AUTOSAR XML (schema 4-2-2)
package /AUTOSAR_NvM/PortInterfaces
  6 x client server interface, all with is-service=true:
    NvMAdmin
      operation SetBlockProtection: possible-error=NvMAdmin/E_NOT_OK
        arg ProtectionEnabled: type=boolean, direction=IN
      error E_NOT_OK: error-code=1
    NvMMirror
      operation ReadRamBlockFromNvM: possible-error=NvMMirror/E_NOT_OK
        arg SrcPtr: type=NvM_Rb_VoidPtr, direction=IN
      operation WriteRamBlockToNvM: possible-error=NvMMirror/E_NOT_OK
        arg DstPtr: type=NvM_Rb_VoidPtr, direction=IN
      error E_NOT_OK: error-code=1
    NvMNotifyInitBlock
      operation InitBlock: possible-error=NvMNotifyInitBlock/E_NOT_OK
      error E_NOT_OK: error-code=1
    NvMNotifyJobFinished
      operation JobFinished: possible-error=NvMNotifyJobFinished/E_NOT_OK
        arg ServiceId: type=uint8, direction=IN
        arg JobResult: type=NvM_RequestResultType, direction=IN
      error E_NOT_OK: error-code=1
    NvMRbNotifyJobStarted
      operation JobStarted
        arg ServiceId: type=uint8, direction=IN
    NvMService
      12 x operation, all with possible-error=NvMService/E_NOT_OK:
        EraseBlock
        GetDataIndex
          arg DataIndexPtr: type=uint8, direction=OUT
        GetErrorStatus
          arg RequestResultPtr: type=NvM_RequestResultType, direction=OUT
        InvalidateNvBlock
        ReadBlock
          arg DstPtr: type=NvM_Rb_VoidPtr, direction=IN
        ReadPRAMBlock
        RestoreBlockDefaults
          arg DstPtr: type=NvM_Rb_VoidPtr, direction=IN
        RestorePRAMBlockDefaults
        SetDataIndex
          arg DataIndex: type=uint8, direction=IN
        SetRamBlockStatus
          arg BlockChanged: type=boolean, direction=IN
        WriteBlock
          arg SrcPtr: type=NvM_Rb_ConstVoidPtr, direction=IN
        WritePRAMBlock
      error E_NOT_OK: error-code=1
package /AUTOSAR_NvM/SwcImplementations
  swc implementation NvM: programming-language=C, swc-bsw-mapping=NvM, vendor-id=6, behavior=NVRAMManager
    code-descriptors:
      code CodeDescriptor: artifact-descriptors=autosar-engineering-object={short-label=ArEngObj, category=SWSRC}
package /AUTOSAR_NvM/SwComponentTypes
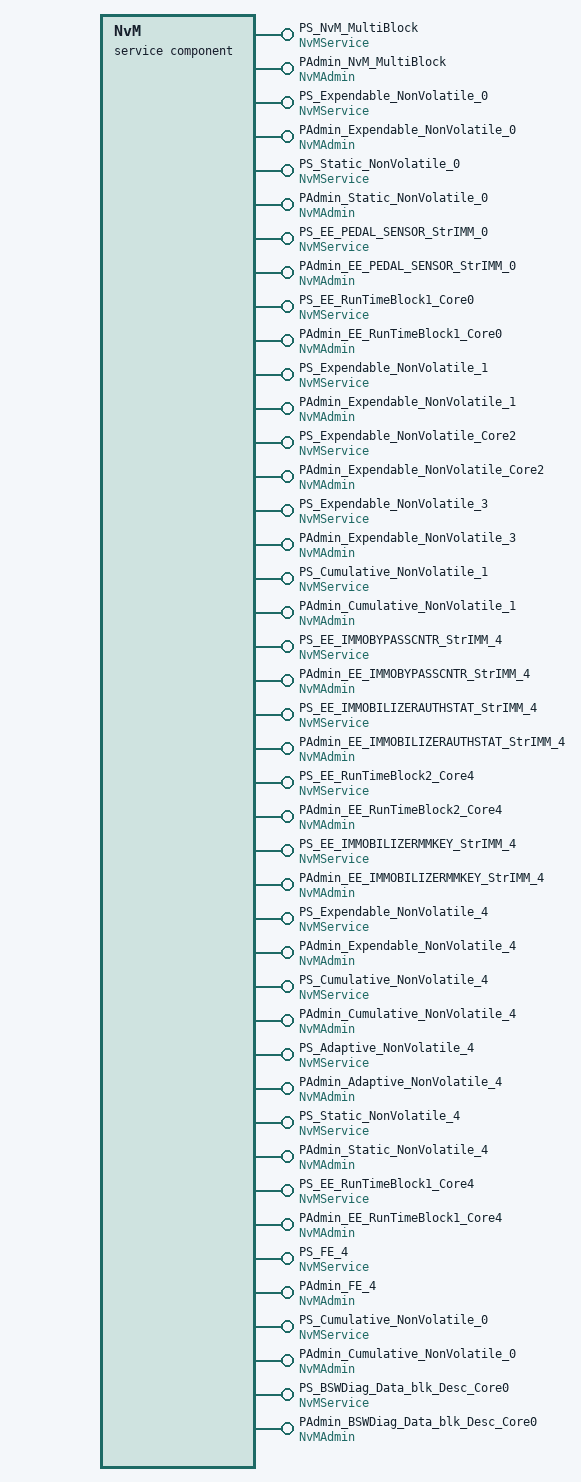
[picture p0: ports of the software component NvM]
  service sw component type NvM
    42 x provide port:
      PS_NvM_MultiBlock: provided-interface=NvMService
        provided-com-specs:
          operation=EraseBlock, queue-length=1
          operation=GetDataIndex, queue-length=1
          operation=GetErrorStatus, queue-length=1
          operation=InvalidateNvBlock, queue-length=1
          operation=ReadBlock, queue-length=1
          operation=ReadPRAMBlock, queue-length=1
          operation=RestoreBlockDefaults, queue-length=1
          operation=RestorePRAMBlockDefaults, queue-length=1
          operation=SetDataIndex, queue-length=1
          operation=SetRamBlockStatus, queue-length=1
          operation=WriteBlock, queue-length=1
          operation=WritePRAMBlock, queue-length=1
      PAdmin_NvM_MultiBlock: server-com-spec{operation=SetBlockProtection, queue-length=1}, provided-interface=NvMAdmin
      PS_Expendable_NonVolatile_0: provided-interface=NvMService
        provided-com-specs:
          operation=EraseBlock, queue-length=1
          operation=GetDataIndex, queue-length=1
          operation=GetErrorStatus, queue-length=1
          operation=InvalidateNvBlock, queue-length=1
          operation=ReadBlock, queue-length=1
          operation=ReadPRAMBlock, queue-length=1
          operation=RestoreBlockDefaults, queue-length=1
          operation=RestorePRAMBlockDefaults, queue-length=1
          operation=SetDataIndex, queue-length=1
          operation=SetRamBlockStatus, queue-length=1
          operation=WriteBlock, queue-length=1
          operation=WritePRAMBlock, queue-length=1
      PAdmin_Expendable_NonVolatile_0: server-com-spec{operation=SetBlockProtection, queue-length=1}, provided-interface=NvMAdmin
      PS_Static_NonVolatile_0: provided-interface=NvMService
        provided-com-specs:
          operation=EraseBlock, queue-length=1
          operation=GetDataIndex, queue-length=1
          operation=GetErrorStatus, queue-length=1
          operation=InvalidateNvBlock, queue-length=1
          operation=ReadBlock, queue-length=1
          operation=ReadPRAMBlock, queue-length=1
          operation=RestoreBlockDefaults, queue-length=1
          operation=RestorePRAMBlockDefaults, queue-length=1
          operation=SetDataIndex, queue-length=1
          operation=SetRamBlockStatus, queue-length=1
          operation=WriteBlock, queue-length=1
          operation=WritePRAMBlock, queue-length=1
      PAdmin_Static_NonVolatile_0: server-com-spec{operation=SetBlockProtection, queue-length=1}, provided-interface=NvMAdmin
      PS_EE_PEDAL_SENSOR_StrIMM_0: provided-interface=NvMService
        provided-com-specs:
          operation=EraseBlock, queue-length=1
          operation=GetDataIndex, queue-length=1
          operation=GetErrorStatus, queue-length=1
          operation=InvalidateNvBlock, queue-length=1
          operation=ReadBlock, queue-length=1
          operation=ReadPRAMBlock, queue-length=1
          operation=RestoreBlockDefaults, queue-length=1
          operation=RestorePRAMBlockDefaults, queue-length=1
          operation=SetDataIndex, queue-length=1
          operation=SetRamBlockStatus, queue-length=1
          operation=WriteBlock, queue-length=1
          operation=WritePRAMBlock, queue-length=1
      PAdmin_EE_PEDAL_SENSOR_StrIMM_0: server-com-spec{operation=SetBlockProtection, queue-length=1}, provided-interface=NvMAdmin
      PS_EE_RunTimeBlock1_Core0: provided-interface=NvMService
        provided-com-specs:
          operation=EraseBlock, queue-length=1
          operation=GetDataIndex, queue-length=1
          operation=GetErrorStatus, queue-length=1
          operation=InvalidateNvBlock, queue-length=1
          operation=ReadBlock, queue-length=1
          operation=ReadPRAMBlock, queue-length=1
          operation=RestoreBlockDefaults, queue-length=1
          operation=RestorePRAMBlockDefaults, queue-length=1
          operation=SetDataIndex, queue-length=1
          operation=SetRamBlockStatus, queue-length=1
          operation=WriteBlock, queue-length=1
          operation=WritePRAMBlock, queue-length=1
      PAdmin_EE_RunTimeBlock1_Core0: server-com-spec{operation=SetBlockProtection, queue-length=1}, provided-interface=NvMAdmin
      PS_Expendable_NonVolatile_1: provided-interface=NvMService
        provided-com-specs:
          operation=EraseBlock, queue-length=1
          operation=GetDataIndex, queue-length=1
          operation=GetErrorStatus, queue-length=1
          operation=InvalidateNvBlock, queue-length=1
          operation=ReadBlock, queue-length=1
          operation=ReadPRAMBlock, queue-length=1
          operation=RestoreBlockDefaults, queue-length=1
          operation=RestorePRAMBlockDefaults, queue-length=1
          operation=SetDataIndex, queue-length=1
          operation=SetRamBlockStatus, queue-length=1
          operation=WriteBlock, queue-length=1
          operation=WritePRAMBlock, queue-length=1
      PAdmin_Expendable_NonVolatile_1: server-com-spec{operation=SetBlockProtection, queue-length=1}, provided-interface=NvMAdmin
      PS_Expendable_NonVolatile_Core2: provided-interface=NvMService
        provided-com-specs:
          operation=EraseBlock, queue-length=1
          operation=GetDataIndex, queue-length=1
          operation=GetErrorStatus, queue-length=1
          operation=InvalidateNvBlock, queue-length=1
          operation=ReadBlock, queue-length=1
          operation=ReadPRAMBlock, queue-length=1
          operation=RestoreBlockDefaults, queue-length=1
          operation=RestorePRAMBlockDefaults, queue-length=1
          operation=SetDataIndex, queue-length=1
          operation=SetRamBlockStatus, queue-length=1
          operation=WriteBlock, queue-length=1
          operation=WritePRAMBlock, queue-length=1
      PAdmin_Expendable_NonVolatile_Core2: server-com-spec{operation=SetBlockProtection, queue-length=1}, provided-interface=NvMAdmin
      PS_Expendable_NonVolatile_3: provided-interface=NvMService
        provided-com-specs:
          operation=EraseBlock, queue-length=1
          operation=GetDataIndex, queue-length=1
          operation=GetErrorStatus, queue-length=1
          operation=InvalidateNvBlock, queue-length=1
          operation=ReadBlock, queue-length=1
          operation=ReadPRAMBlock, queue-length=1
          operation=RestoreBlockDefaults, queue-length=1
          operation=RestorePRAMBlockDefaults, queue-length=1
          operation=SetDataIndex, queue-length=1
          operation=SetRamBlockStatus, queue-length=1
          operation=WriteBlock, queue-length=1
          operation=WritePRAMBlock, queue-length=1
      PAdmin_Expendable_NonVolatile_3: server-com-spec{operation=SetBlockProtection, queue-length=1}, provided-interface=NvMAdmin
      PS_Cumulative_NonVolatile_1: provided-interface=NvMService
        provided-com-specs:
          operation=EraseBlock, queue-length=1
          operation=GetDataIndex, queue-length=1
          operation=GetErrorStatus, queue-length=1
          operation=InvalidateNvBlock, queue-length=1
          operation=ReadBlock, queue-length=1
          operation=ReadPRAMBlock, queue-length=1
          operation=RestoreBlockDefaults, queue-length=1
          operation=RestorePRAMBlockDefaults, queue-length=1
          operation=SetDataIndex, queue-length=1
          operation=SetRamBlockStatus, queue-length=1
          operation=WriteBlock, queue-length=1
          operation=WritePRAMBlock, queue-length=1
      PAdmin_Cumulative_NonVolatile_1: server-com-spec{operation=SetBlockProtection, queue-length=1}, provided-interface=NvMAdmin
      PS_EE_IMMOBYPASSCNTR_StrIMM_4: provided-interface=NvMService
        provided-com-specs:
          operation=EraseBlock, queue-length=1
          operation=GetDataIndex, queue-length=1
          operation=GetErrorStatus, queue-length=1
          operation=InvalidateNvBlock, queue-length=1
          operation=ReadBlock, queue-length=1
          operation=ReadPRAMBlock, queue-length=1
          operation=RestoreBlockDefaults, queue-length=1
          operation=RestorePRAMBlockDefaults, queue-length=1
          operation=SetDataIndex, queue-length=1
          operation=SetRamBlockStatus, queue-length=1
          operation=WriteBlock, queue-length=1
          operation=WritePRAMBlock, queue-length=1
      PAdmin_EE_IMMOBYPASSCNTR_StrIMM_4: server-com-spec{operation=SetBlockProtection, queue-length=1}, provided-interface=NvMAdmin
      PS_EE_IMMOBILIZERAUTHSTAT_StrIMM_4: provided-interface=NvMService
        provided-com-specs:
          operation=EraseBlock, queue-length=1
          operation=GetDataIndex, queue-length=1
          operation=GetErrorStatus, queue-length=1
          operation=InvalidateNvBlock, queue-length=1
          operation=ReadBlock, queue-length=1
          operation=ReadPRAMBlock, queue-length=1
          operation=RestoreBlockDefaults, queue-length=1
          operation=RestorePRAMBlockDefaults, queue-length=1
          operation=SetDataIndex, queue-length=1
          operation=SetRamBlockStatus, queue-length=1
          operation=WriteBlock, queue-length=1
          operation=WritePRAMBlock, queue-length=1
      PAdmin_EE_IMMOBILIZERAUTHSTAT_StrIMM_4: server-com-spec{operation=SetBlockProtection, queue-length=1}, provided-interface=NvMAdmin
      PS_EE_RunTimeBlock2_Core4: provided-interface=NvMService
        provided-com-specs:
          operation=EraseBlock, queue-length=1
          operation=GetDataIndex, queue-length=1
          operation=GetErrorStatus, queue-length=1
          operation=InvalidateNvBlock, queue-length=1
          operation=ReadBlock, queue-length=1
          operation=ReadPRAMBlock, queue-length=1
          operation=RestoreBlockDefaults, queue-length=1
          operation=RestorePRAMBlockDefaults, queue-length=1
          operation=SetDataIndex, queue-length=1
          operation=SetRamBlockStatus, queue-length=1
          operation=WriteBlock, queue-length=1
          operation=WritePRAMBlock, queue-length=1
      PAdmin_EE_RunTimeBlock2_Core4: server-com-spec{operation=SetBlockProtection, queue-length=1}, provided-interface=NvMAdmin
      PS_EE_IMMOBILIZERMMKEY_StrIMM_4: provided-interface=NvMService
        provided-com-specs:
          operation=EraseBlock, queue-length=1
          operation=GetDataIndex, queue-length=1
          operation=GetErrorStatus, queue-length=1
          operation=InvalidateNvBlock, queue-length=1
          operation=ReadBlock, queue-length=1
          operation=ReadPRAMBlock, queue-length=1
          operation=RestoreBlockDefaults, queue-length=1
          operation=RestorePRAMBlockDefaults, queue-length=1
          operation=SetDataIndex, queue-length=1
          operation=SetRamBlockStatus, queue-length=1
          operation=WriteBlock, queue-length=1
          operation=WritePRAMBlock, queue-length=1
      PAdmin_EE_IMMOBILIZERMMKEY_StrIMM_4: server-com-spec{operation=SetBlockProtection, queue-length=1}, provided-interface=NvMAdmin
      PS_Expendable_NonVolatile_4: provided-interface=NvMService
        provided-com-specs:
          operation=EraseBlock, queue-length=1
          operation=GetDataIndex, queue-length=1
          operation=GetErrorStatus, queue-length=1
          operation=InvalidateNvBlock, queue-length=1
          operation=ReadBlock, queue-length=1
          operation=ReadPRAMBlock, queue-length=1
          operation=RestoreBlockDefaults, queue-length=1
          operation=RestorePRAMBlockDefaults, queue-length=1
          operation=SetDataIndex, queue-length=1
          operation=SetRamBlockStatus, queue-length=1
          operation=WriteBlock, queue-length=1
          operation=WritePRAMBlock, queue-length=1
      PAdmin_Expendable_NonVolatile_4: server-com-spec{operation=SetBlockProtection, queue-length=1}, provided-interface=NvMAdmin
      PS_Cumulative_NonVolatile_4: provided-interface=NvMService
        provided-com-specs:
          operation=EraseBlock, queue-length=1
          operation=GetDataIndex, queue-length=1
          operation=GetErrorStatus, queue-length=1
          operation=InvalidateNvBlock, queue-length=1
          operation=ReadBlock, queue-length=1
          operation=ReadPRAMBlock, queue-length=1
          operation=RestoreBlockDefaults, queue-length=1
          operation=RestorePRAMBlockDefaults, queue-length=1
          operation=SetDataIndex, queue-length=1
          operation=SetRamBlockStatus, queue-length=1
          operation=WriteBlock, queue-length=1
          operation=WritePRAMBlock, queue-length=1
      PAdmin_Cumulative_NonVolatile_4: server-com-spec{operation=SetBlockProtection, queue-length=1}, provided-interface=NvMAdmin
      PS_Adaptive_NonVolatile_4: provided-interface=NvMService
        provided-com-specs:
          operation=EraseBlock, queue-length=1
          operation=GetDataIndex, queue-length=1
          operation=GetErrorStatus, queue-length=1
          operation=InvalidateNvBlock, queue-length=1
          operation=ReadBlock, queue-length=1
          operation=ReadPRAMBlock, queue-length=1
          operation=RestoreBlockDefaults, queue-length=1
          operation=RestorePRAMBlockDefaults, queue-length=1
          operation=SetDataIndex, queue-length=1
          operation=SetRamBlockStatus, queue-length=1
          operation=WriteBlock, queue-length=1
          operation=WritePRAMBlock, queue-length=1
      PAdmin_Adaptive_NonVolatile_4: server-com-spec{operation=SetBlockProtection, queue-length=1}, provided-interface=NvMAdmin
      PS_Static_NonVolatile_4: provided-interface=NvMService
        provided-com-specs:
          operation=EraseBlock, queue-length=1
          operation=GetDataIndex, queue-length=1
          operation=GetErrorStatus, queue-length=1
          operation=InvalidateNvBlock, queue-length=1
          operation=ReadBlock, queue-length=1
          operation=ReadPRAMBlock, queue-length=1
          operation=RestoreBlockDefaults, queue-length=1
          operation=RestorePRAMBlockDefaults, queue-length=1
          operation=SetDataIndex, queue-length=1
          operation=SetRamBlockStatus, queue-length=1
          operation=WriteBlock, queue-length=1
          operation=WritePRAMBlock, queue-length=1
      PAdmin_Static_NonVolatile_4: server-com-spec{operation=SetBlockProtection, queue-length=1}, provided-interface=NvMAdmin
      PS_EE_RunTimeBlock1_Core4: provided-interface=NvMService
        provided-com-specs:
          operation=EraseBlock, queue-length=1
          operation=GetDataIndex, queue-length=1
          operation=GetErrorStatus, queue-length=1
          operation=InvalidateNvBlock, queue-length=1
          operation=ReadBlock, queue-length=1
          operation=ReadPRAMBlock, queue-length=1
          operation=RestoreBlockDefaults, queue-length=1
          operation=RestorePRAMBlockDefaults, queue-length=1
          operation=SetDataIndex, queue-length=1
          operation=SetRamBlockStatus, queue-length=1
          operation=WriteBlock, queue-length=1
          operation=WritePRAMBlock, queue-length=1
      PAdmin_EE_RunTimeBlock1_Core4: server-com-spec{operation=SetBlockProtection, queue-length=1}, provided-interface=NvMAdmin
      PS_FE_4: provided-interface=NvMService
        provided-com-specs:
          operation=EraseBlock, queue-length=1
          operation=GetDataIndex, queue-length=1
          operation=GetErrorStatus, queue-length=1
          operation=InvalidateNvBlock, queue-length=1
          operation=ReadBlock, queue-length=1
          operation=ReadPRAMBlock, queue-length=1
          operation=RestoreBlockDefaults, queue-length=1
          operation=RestorePRAMBlockDefaults, queue-length=1
          operation=SetDataIndex, queue-length=1
          operation=SetRamBlockStatus, queue-length=1
          operation=WriteBlock, queue-length=1
          operation=WritePRAMBlock, queue-length=1
      PAdmin_FE_4: server-com-spec{operation=SetBlockProtection, queue-length=1}, provided-interface=NvMAdmin
      PS_Cumulative_NonVolatile_0: provided-interface=NvMService
        provided-com-specs:
          operation=EraseBlock, queue-length=1
          operation=GetDataIndex, queue-length=1
          operation=GetErrorStatus, queue-length=1
          operation=InvalidateNvBlock, queue-length=1
          operation=ReadBlock, queue-length=1
          operation=ReadPRAMBlock, queue-length=1
          operation=RestoreBlockDefaults, queue-length=1
          operation=RestorePRAMBlockDefaults, queue-length=1
          operation=SetDataIndex, queue-length=1
          operation=SetRamBlockStatus, queue-length=1
          operation=WriteBlock, queue-length=1
          operation=WritePRAMBlock, queue-length=1
      PAdmin_Cumulative_NonVolatile_0: server-com-spec{operation=SetBlockProtection, queue-length=1}, provided-interface=NvMAdmin
      PS_BSWDiag_Data_blk_Desc_Core0: provided-interface=NvMService
        provided-com-specs:
          operation=EraseBlock, queue-length=1
          operation=GetDataIndex, queue-length=1
          operation=GetErrorStatus, queue-length=1
          operation=InvalidateNvBlock, queue-length=1
          operation=ReadBlock, queue-length=1
          operation=ReadPRAMBlock, queue-length=1
          operation=RestoreBlockDefaults, queue-length=1
          operation=RestorePRAMBlockDefaults, queue-length=1
          operation=SetDataIndex, queue-length=1
          operation=SetRamBlockStatus, queue-length=1
          operation=WriteBlock, queue-length=1
          operation=WritePRAMBlock, queue-length=1
      PAdmin_BSWDiag_Data_blk_Desc_Core0: server-com-spec{operation=SetBlockProtection, queue-length=1}, provided-interface=NvMAdmin
    behavior NVRAMManager
      273 x operation invoked event:
        EENB_NvM_MultiBlock: start-on-event=EraseNvBlock, operation=PS_NvM_MultiBlock.EraseBlock
        EGDI_NvM_MultiBlock: start-on-event=GetDataIndex, operation=PS_NvM_MultiBlock.GetDataIndex
        EGES_NvM_MultiBlock: start-on-event=GetErrorStatus, operation=PS_NvM_MultiBlock.GetErrorStatus
        EINB_NvM_MultiBlock: start-on-event=InvalidateNvBlock, operation=PS_NvM_MultiBlock.InvalidateNvBlock
        ERBL_NvM_MultiBlock: start-on-event=ReadBlock, operation=PS_NvM_MultiBlock.ReadBlock
        ERPBL_NvM_MultiBlock: start-on-event=ReadPRAMBlock, operation=PS_NvM_MultiBlock.ReadPRAMBlock
        ERBD_NvM_MultiBlock: start-on-event=RestoreBlockDefaults, operation=PS_NvM_MultiBlock.RestoreBlockDefaults
        ERPBD_NvM_MultiBlock: start-on-event=RestorePRAMBlockDefaults, operation=PS_NvM_MultiBlock.RestorePRAMBlockDefaults
        ESBP_NvM_MultiBlock: start-on-event=SetBlockProtection, operation=PAdmin_NvM_MultiBlock.SetBlockProtection
        ESDI_NvM_MultiBlock: start-on-event=SetDataIndex, operation=PS_NvM_MultiBlock.SetDataIndex
        ESRS_NvM_MultiBlock: start-on-event=SetRamBlockStatus, operation=PS_NvM_MultiBlock.SetRamBlockStatus
        EWBL_NvM_MultiBlock: start-on-event=WriteBlock, operation=PS_NvM_MultiBlock.WriteBlock
        EWPBL_NvM_MultiBlock: start-on-event=WritePRAMBlock, operation=PS_NvM_MultiBlock.WritePRAMBlock
        EENB_Expendable_NonVolatile_0: start-on-event=EraseNvBlock, operation=PS_Expendable_NonVolatile_0.EraseBlock
        EGDI_Expendable_NonVolatile_0: start-on-event=GetDataIndex, operation=PS_Expendable_NonVolatile_0.GetDataIndex
        EGES_Expendable_NonVolatile_0: start-on-event=GetErrorStatus, operation=PS_Expendable_NonVolatile_0.GetErrorStatus
        EINB_Expendable_NonVolatile_0: start-on-event=InvalidateNvBlock, operation=PS_Expendable_NonVolatile_0.InvalidateNvBlock
        ERBL_Expendable_NonVolatile_0: start-on-event=ReadBlock, operation=PS_Expendable_NonVolatile_0.ReadBlock
        ERPBL_Expendable_NonVolatile_0: start-on-event=ReadPRAMBlock, operation=PS_Expendable_NonVolatile_0.ReadPRAMBlock
        ERBD_Expendable_NonVolatile_0: start-on-event=RestoreBlockDefaults, operation=PS_Expendable_NonVolatile_0.RestoreBlockDefaults
        ERPBD_Expendable_NonVolatile_0: start-on-event=RestorePRAMBlockDefaults, operation=PS_Expendable_NonVolatile_0.RestorePRAMBlockDefaults
        ESBP_Expendable_NonVolatile_0: start-on-event=SetBlockProtection, operation=PAdmin_Expendable_NonVolatile_0.SetBlockProtection
        ESDI_Expendable_NonVolatile_0: start-on-event=SetDataIndex, operation=PS_Expendable_NonVolatile_0.SetDataIndex
        ESRS_Expendable_NonVolatile_0: start-on-event=SetRamBlockStatus, operation=PS_Expendable_NonVolatile_0.SetRamBlockStatus
        EWBL_Expendable_NonVolatile_0: start-on-event=WriteBlock, operation=PS_Expendable_NonVolatile_0.WriteBlock
        EWPBL_Expendable_NonVolatile_0: start-on-event=WritePRAMBlock, operation=PS_Expendable_NonVolatile_0.WritePRAMBlock
        EENB_Static_NonVolatile_0: start-on-event=EraseNvBlock, operation=PS_Static_NonVolatile_0.EraseBlock
        EGDI_Static_NonVolatile_0: start-on-event=GetDataIndex, operation=PS_Static_NonVolatile_0.GetDataIndex
        EGES_Static_NonVolatile_0: start-on-event=GetErrorStatus, operation=PS_Static_NonVolatile_0.GetErrorStatus
        EINB_Static_NonVolatile_0: start-on-event=InvalidateNvBlock, operation=PS_Static_NonVolatile_0.InvalidateNvBlock
        ERBL_Static_NonVolatile_0: start-on-event=ReadBlock, operation=PS_Static_NonVolatile_0.ReadBlock
        ERPBL_Static_NonVolatile_0: start-on-event=ReadPRAMBlock, operation=PS_Static_NonVolatile_0.ReadPRAMBlock
        ERBD_Static_NonVolatile_0: start-on-event=RestoreBlockDefaults, operation=PS_Static_NonVolatile_0.RestoreBlockDefaults
        ERPBD_Static_NonVolatile_0: start-on-event=RestorePRAMBlockDefaults, operation=PS_Static_NonVolatile_0.RestorePRAMBlockDefaults
        ESBP_Static_NonVolatile_0: start-on-event=SetBlockProtection, operation=PAdmin_Static_NonVolatile_0.SetBlockProtection
        ESDI_Static_NonVolatile_0: start-on-event=SetDataIndex, operation=PS_Static_NonVolatile_0.SetDataIndex
        ESRS_Static_NonVolatile_0: start-on-event=SetRamBlockStatus, operation=PS_Static_NonVolatile_0.SetRamBlockStatus
        EWBL_Static_NonVolatile_0: start-on-event=WriteBlock, operation=PS_Static_NonVolatile_0.WriteBlock
        EWPBL_Static_NonVolatile_0: start-on-event=WritePRAMBlock, operation=PS_Static_NonVolatile_0.WritePRAMBlock
        EENB_EE_PEDAL_SENSOR_StrIMM_0: start-on-event=EraseNvBlock, operation=PS_EE_PEDAL_SENSOR_StrIMM_0.EraseBlock
        EGDI_EE_PEDAL_SENSOR_StrIMM_0: start-on-event=GetDataIndex, operation=PS_EE_PEDAL_SENSOR_StrIMM_0.GetDataIndex
        EGES_EE_PEDAL_SENSOR_StrIMM_0: start-on-event=GetErrorStatus, operation=PS_EE_PEDAL_SENSOR_StrIMM_0.GetErrorStatus
        EINB_EE_PEDAL_SENSOR_StrIMM_0: start-on-event=InvalidateNvBlock, operation=PS_EE_PEDAL_SENSOR_StrIMM_0.InvalidateNvBlock
        ERBL_EE_PEDAL_SENSOR_StrIMM_0: start-on-event=ReadBlock, operation=PS_EE_PEDAL_SENSOR_StrIMM_0.ReadBlock
        ERPBL_EE_PEDAL_SENSOR_StrIMM_0: start-on-event=ReadPRAMBlock, operation=PS_EE_PEDAL_SENSOR_StrIMM_0.ReadPRAMBlock
        ERBD_EE_PEDAL_SENSOR_StrIMM_0: start-on-event=RestoreBlockDefaults, operation=PS_EE_PEDAL_SENSOR_StrIMM_0.RestoreBlockDefaults
        ERPBD_EE_PEDAL_SENSOR_StrIMM_0: start-on-event=RestorePRAMBlockDefaults, operation=PS_EE_PEDAL_SENSOR_StrIMM_0.RestorePRAMBlockDefaults
        ESBP_EE_PEDAL_SENSOR_StrIMM_0: start-on-event=SetBlockProtection, operation=PAdmin_EE_PEDAL_SENSOR_StrIMM_0.SetBlockProtection
        ESDI_EE_PEDAL_SENSOR_StrIMM_0: start-on-event=SetDataIndex, operation=PS_EE_PEDAL_SENSOR_StrIMM_0.SetDataIndex
        ESRS_EE_PEDAL_SENSOR_StrIMM_0: start-on-event=SetRamBlockStatus, operation=PS_EE_PEDAL_SENSOR_StrIMM_0.SetRamBlockStatus
        EWBL_EE_PEDAL_SENSOR_StrIMM_0: start-on-event=WriteBlock, operation=PS_EE_PEDAL_SENSOR_StrIMM_0.WriteBlock
        EWPBL_EE_PEDAL_SENSOR_StrIMM_0: start-on-event=WritePRAMBlock, operation=PS_EE_PEDAL_SENSOR_StrIMM_0.WritePRAMBlock
        EENB_EE_RunTimeBlock1_Core0: start-on-event=EraseNvBlock, operation=PS_EE_RunTimeBlock1_Core0.EraseBlock
        EGDI_EE_RunTimeBlock1_Core0: start-on-event=GetDataIndex, operation=PS_EE_RunTimeBlock1_Core0.GetDataIndex
        EGES_EE_RunTimeBlock1_Core0: start-on-event=GetErrorStatus, operation=PS_EE_RunTimeBlock1_Core0.GetErrorStatus
        EINB_EE_RunTimeBlock1_Core0: start-on-event=InvalidateNvBlock, operation=PS_EE_RunTimeBlock1_Core0.InvalidateNvBlock
        ERBL_EE_RunTimeBlock1_Core0: start-on-event=ReadBlock, operation=PS_EE_RunTimeBlock1_Core0.ReadBlock
        ERPBL_EE_RunTimeBlock1_Core0: start-on-event=ReadPRAMBlock, operation=PS_EE_RunTimeBlock1_Core0.ReadPRAMBlock
        ERBD_EE_RunTimeBlock1_Core0: start-on-event=RestoreBlockDefaults, operation=PS_EE_RunTimeBlock1_Core0.RestoreBlockDefaults
        ERPBD_EE_RunTimeBlock1_Core0: start-on-event=RestorePRAMBlockDefaults, operation=PS_EE_RunTimeBlock1_Core0.RestorePRAMBlockDefaults
        ESBP_EE_RunTimeBlock1_Core0: start-on-event=SetBlockProtection, operation=PAdmin_EE_RunTimeBlock1_Core0.SetBlockProtection
        ESDI_EE_RunTimeBlock1_Core0: start-on-event=SetDataIndex, operation=PS_EE_RunTimeBlock1_Core0.SetDataIndex
        ESRS_EE_RunTimeBlock1_Core0: start-on-event=SetRamBlockStatus, operation=PS_EE_RunTimeBlock1_Core0.SetRamBlockStatus
        EWBL_EE_RunTimeBlock1_Core0: start-on-event=WriteBlock, operation=PS_EE_RunTimeBlock1_Core0.WriteBlock
        EWPBL_EE_RunTimeBlock1_Core0: start-on-event=WritePRAMBlock, operation=PS_EE_RunTimeBlock1_Core0.WritePRAMBlock
        EENB_Expendable_NonVolatile_1: start-on-event=EraseNvBlock, operation=PS_Expendable_NonVolatile_1.EraseBlock
        EGDI_Expendable_NonVolatile_1: start-on-event=GetDataIndex, operation=PS_Expendable_NonVolatile_1.GetDataIndex
        EGES_Expendable_NonVolatile_1: start-on-event=GetErrorStatus, operation=PS_Expendable_NonVolatile_1.GetErrorStatus
        EINB_Expendable_NonVolatile_1: start-on-event=InvalidateNvBlock, operation=PS_Expendable_NonVolatile_1.InvalidateNvBlock
        ERBL_Expendable_NonVolatile_1: start-on-event=ReadBlock, operation=PS_Expendable_NonVolatile_1.ReadBlock
        ERPBL_Expendable_NonVolatile_1: start-on-event=ReadPRAMBlock, operation=PS_Expendable_NonVolatile_1.ReadPRAMBlock
        ERBD_Expendable_NonVolatile_1: start-on-event=RestoreBlockDefaults, operation=PS_Expendable_NonVolatile_1.RestoreBlockDefaults
        ERPBD_Expendable_NonVolatile_1: start-on-event=RestorePRAMBlockDefaults, operation=PS_Expendable_NonVolatile_1.RestorePRAMBlockDefaults
        ESBP_Expendable_NonVolatile_1: start-on-event=SetBlockProtection, operation=PAdmin_Expendable_NonVolatile_1.SetBlockProtection
        ESDI_Expendable_NonVolatile_1: start-on-event=SetDataIndex, operation=PS_Expendable_NonVolatile_1.SetDataIndex
        ESRS_Expendable_NonVolatile_1: start-on-event=SetRamBlockStatus, operation=PS_Expendable_NonVolatile_1.SetRamBlockStatus
        EWBL_Expendable_NonVolatile_1: start-on-event=WriteBlock, operation=PS_Expendable_NonVolatile_1.WriteBlock
        EWPBL_Expendable_NonVolatile_1: start-on-event=WritePRAMBlock, operation=PS_Expendable_NonVolatile_1.WritePRAMBlock
        EENB_Expendable_NonVolatile_Core2: start-on-event=EraseNvBlock, operation=PS_Expendable_NonVolatile_Core2.EraseBlock
        EGDI_Expendable_NonVolatile_Core2: start-on-event=GetDataIndex, operation=PS_Expendable_NonVolatile_Core2.GetDataIndex
        EGES_Expendable_NonVolatile_Core2: start-on-event=GetErrorStatus, operation=PS_Expendable_NonVolatile_Core2.GetErrorStatus
        EINB_Expendable_NonVolatile_Core2: start-on-event=InvalidateNvBlock, operation=PS_Expendable_NonVolatile_Core2.InvalidateNvBlock
        ERBL_Expendable_NonVolatile_Core2: start-on-event=ReadBlock, operation=PS_Expendable_NonVolatile_Core2.ReadBlock
        ERPBL_Expendable_NonVolatile_Core2: start-on-event=ReadPRAMBlock, operation=PS_Expendable_NonVolatile_Core2.ReadPRAMBlock
        ERBD_Expendable_NonVolatile_Core2: start-on-event=RestoreBlockDefaults, operation=PS_Expendable_NonVolatile_Core2.RestoreBlockDefaults
        ERPBD_Expendable_NonVolatile_Core2: start-on-event=RestorePRAMBlockDefaults, operation=PS_Expendable_NonVolatile_Core2.RestorePRAMBlockDefaults
        ESBP_Expendable_NonVolatile_Core2: start-on-event=SetBlockProtection, operation=PAdmin_Expendable_NonVolatile_Core2.SetBlockProtection
        ESDI_Expendable_NonVolatile_Core2: start-on-event=SetDataIndex, operation=PS_Expendable_NonVolatile_Core2.SetDataIndex
        ESRS_Expendable_NonVolatile_Core2: start-on-event=SetRamBlockStatus, operation=PS_Expendable_NonVolatile_Core2.SetRamBlockStatus
        EWBL_Expendable_NonVolatile_Core2: start-on-event=WriteBlock, operation=PS_Expendable_NonVolatile_Core2.WriteBlock
        EWPBL_Expendable_NonVolatile_Core2: start-on-event=WritePRAMBlock, operation=PS_Expendable_NonVolatile_Core2.WritePRAMBlock
        EENB_Expendable_NonVolatile_3: start-on-event=EraseNvBlock, operation=PS_Expendable_NonVolatile_3.EraseBlock
        EGDI_Expendable_NonVolatile_3: start-on-event=GetDataIndex, operation=PS_Expendable_NonVolatile_3.GetDataIndex
        EGES_Expendable_NonVolatile_3: start-on-event=GetErrorStatus, operation=PS_Expendable_NonVolatile_3.GetErrorStatus
        EINB_Expendable_NonVolatile_3: start-on-event=InvalidateNvBlock, operation=PS_Expendable_NonVolatile_3.InvalidateNvBlock
        ERBL_Expendable_NonVolatile_3: start-on-event=ReadBlock, operation=PS_Expendable_NonVolatile_3.ReadBlock
        ERPBL_Expendable_NonVolatile_3: start-on-event=ReadPRAMBlock, operation=PS_Expendable_NonVolatile_3.ReadPRAMBlock
        ERBD_Expendable_NonVolatile_3: start-on-event=RestoreBlockDefaults, operation=PS_Expendable_NonVolatile_3.RestoreBlockDefaults
        ERPBD_Expendable_NonVolatile_3: start-on-event=RestorePRAMBlockDefaults, operation=PS_Expendable_NonVolatile_3.RestorePRAMBlockDefaults
        ESBP_Expendable_NonVolatile_3: start-on-event=SetBlockProtection, operation=PAdmin_Expendable_NonVolatile_3.SetBlockProtection
        ESDI_Expendable_NonVolatile_3: start-on-event=SetDataIndex, operation=PS_Expendable_NonVolatile_3.SetDataIndex
        ESRS_Expendable_NonVolatile_3: start-on-event=SetRamBlockStatus, operation=PS_Expendable_NonVolatile_3.SetRamBlockStatus
        EWBL_Expendable_NonVolatile_3: start-on-event=WriteBlock, operation=PS_Expendable_NonVolatile_3.WriteBlock
        EWPBL_Expendable_NonVolatile_3: start-on-event=WritePRAMBlock, operation=PS_Expendable_NonVolatile_3.WritePRAMBlock
        EENB_Cumulative_NonVolatile_1: start-on-event=EraseNvBlock, operation=PS_Cumulative_NonVolatile_1.EraseBlock
        EGDI_Cumulative_NonVolatile_1: start-on-event=GetDataIndex, operation=PS_Cumulative_NonVolatile_1.GetDataIndex
        EGES_Cumulative_NonVolatile_1: start-on-event=GetErrorStatus, operation=PS_Cumulative_NonVolatile_1.GetErrorStatus
        EINB_Cumulative_NonVolatile_1: start-on-event=InvalidateNvBlock, operation=PS_Cumulative_NonVolatile_1.InvalidateNvBlock
        ERBL_Cumulative_NonVolatile_1: start-on-event=ReadBlock, operation=PS_Cumulative_NonVolatile_1.ReadBlock
        ERPBL_Cumulative_NonVolatile_1: start-on-event=ReadPRAMBlock, operation=PS_Cumulative_NonVolatile_1.ReadPRAMBlock
        ERBD_Cumulative_NonVolatile_1: start-on-event=RestoreBlockDefaults, operation=PS_Cumulative_NonVolatile_1.RestoreBlockDefaults
        ERPBD_Cumulative_NonVolatile_1: start-on-event=RestorePRAMBlockDefaults, operation=PS_Cumulative_NonVolatile_1.RestorePRAMBlockDefaults
        ESBP_Cumulative_NonVolatile_1: start-on-event=SetBlockProtection, operation=PAdmin_Cumulative_NonVolatile_1.SetBlockProtection
        ESDI_Cumulative_NonVolatile_1: start-on-event=SetDataIndex, operation=PS_Cumulative_NonVolatile_1.SetDataIndex
        ESRS_Cumulative_NonVolatile_1: start-on-event=SetRamBlockStatus, operation=PS_Cumulative_NonVolatile_1.SetRamBlockStatus
        EWBL_Cumulative_NonVolatile_1: start-on-event=WriteBlock, operation=PS_Cumulative_NonVolatile_1.WriteBlock
        EWPBL_Cumulative_NonVolatile_1: start-on-event=WritePRAMBlock, operation=PS_Cumulative_NonVolatile_1.WritePRAMBlock
        EENB_EE_IMMOBYPASSCNTR_StrIMM_4: start-on-event=EraseNvBlock, operation=PS_EE_IMMOBYPASSCNTR_StrIMM_4.EraseBlock
        EGDI_EE_IMMOBYPASSCNTR_StrIMM_4: start-on-event=GetDataIndex, operation=PS_EE_IMMOBYPASSCNTR_StrIMM_4.GetDataIndex
        EGES_EE_IMMOBYPASSCNTR_StrIMM_4: start-on-event=GetErrorStatus, operation=PS_EE_IMMOBYPASSCNTR_StrIMM_4.GetErrorStatus
        EINB_EE_IMMOBYPASSCNTR_StrIMM_4: start-on-event=InvalidateNvBlock, operation=PS_EE_IMMOBYPASSCNTR_StrIMM_4.InvalidateNvBlock
        ERBL_EE_IMMOBYPASSCNTR_StrIMM_4: start-on-event=ReadBlock, operation=PS_EE_IMMOBYPASSCNTR_StrIMM_4.ReadBlock
        ERPBL_EE_IMMOBYPASSCNTR_StrIMM_4: start-on-event=ReadPRAMBlock, operation=PS_EE_IMMOBYPASSCNTR_StrIMM_4.ReadPRAMBlock
        ERBD_EE_IMMOBYPASSCNTR_StrIMM_4: start-on-event=RestoreBlockDefaults, operation=PS_EE_IMMOBYPASSCNTR_StrIMM_4.RestoreBlockDefaults
        ERPBD_EE_IMMOBYPASSCNTR_StrIMM_4: start-on-event=RestorePRAMBlockDefaults, operation=PS_EE_IMMOBYPASSCNTR_StrIMM_4.RestorePRAMBlockDefaults
        ESBP_EE_IMMOBYPASSCNTR_StrIMM_4: start-on-event=SetBlockProtection, operation=PAdmin_EE_IMMOBYPASSCNTR_StrIMM_4.SetBlockProtection
        ESDI_EE_IMMOBYPASSCNTR_StrIMM_4: start-on-event=SetDataIndex, operation=PS_EE_IMMOBYPASSCNTR_StrIMM_4.SetDataIndex
        ESRS_EE_IMMOBYPASSCNTR_StrIMM_4: start-on-event=SetRamBlockStatus, operation=PS_EE_IMMOBYPASSCNTR_StrIMM_4.SetRamBlockStatus
        EWBL_EE_IMMOBYPASSCNTR_StrIMM_4: start-on-event=WriteBlock, operation=PS_EE_IMMOBYPASSCNTR_StrIMM_4.WriteBlock
        EWPBL_EE_IMMOBYPASSCNTR_StrIMM_4: start-on-event=WritePRAMBlock, operation=PS_EE_IMMOBYPASSCNTR_StrIMM_4.WritePRAMBlock
        EENB_EE_IMMOBILIZERAUTHSTAT_StrIMM_4: start-on-event=EraseNvBlock, operation=PS_EE_IMMOBILIZERAUTHSTAT_StrIMM_4.EraseBlock
        EGDI_EE_IMMOBILIZERAUTHSTAT_StrIMM_4: start-on-event=GetDataIndex, operation=PS_EE_IMMOBILIZERAUTHSTAT_StrIMM_4.GetDataIndex
        EGES_EE_IMMOBILIZERAUTHSTAT_StrIMM_4: start-on-event=GetErrorStatus, operation=PS_EE_IMMOBILIZERAUTHSTAT_StrIMM_4.GetErrorStatus
        EINB_EE_IMMOBILIZERAUTHSTAT_StrIMM_4: start-on-event=InvalidateNvBlock, operation=PS_EE_IMMOBILIZERAUTHSTAT_StrIMM_4.InvalidateNvBlock
        ERBL_EE_IMMOBILIZERAUTHSTAT_StrIMM_4: start-on-event=ReadBlock, operation=PS_EE_IMMOBILIZERAUTHSTAT_StrIMM_4.ReadBlock
        ERPBL_EE_IMMOBILIZERAUTHSTAT_StrIMM_4: start-on-event=ReadPRAMBlock, operation=PS_EE_IMMOBILIZERAUTHSTAT_StrIMM_4.ReadPRAMBlock
        ERBD_EE_IMMOBILIZERAUTHSTAT_StrIMM_4: start-on-event=RestoreBlockDefaults, operation=PS_EE_IMMOBILIZERAUTHSTAT_StrIMM_4.RestoreBlockDefaults
        ERPBD_EE_IMMOBILIZERAUTHSTAT_StrIMM_4: start-on-event=RestorePRAMBlockDefaults, operation=PS_EE_IMMOBILIZERAUTHSTAT_StrIMM_4.RestorePRAMBlockDefaults
        ESBP_EE_IMMOBILIZERAUTHSTAT_StrIMM_4: start-on-event=SetBlockProtection, operation=PAdmin_EE_IMMOBILIZERAUTHSTAT_StrIMM_4.SetBlockProtection
        ESDI_EE_IMMOBILIZERAUTHSTAT_StrIMM_4: start-on-event=SetDataIndex, operation=PS_EE_IMMOBILIZERAUTHSTAT_StrIMM_4.SetDataIndex
        ESRS_EE_IMMOBILIZERAUTHSTAT_StrIMM_4: start-on-event=SetRamBlockStatus, operation=PS_EE_IMMOBILIZERAUTHSTAT_StrIMM_4.SetRamBlockStatus
        EWBL_EE_IMMOBILIZERAUTHSTAT_StrIMM_4: start-on-event=WriteBlock, operation=PS_EE_IMMOBILIZERAUTHSTAT_StrIMM_4.WriteBlock
        EWPBL_EE_IMMOBILIZERAUTHSTAT_StrIMM_4: start-on-event=WritePRAMBlock, operation=PS_EE_IMMOBILIZERAUTHSTAT_StrIMM_4.WritePRAMBlock
        EENB_EE_RunTimeBlock2_Core4: start-on-event=EraseNvBlock, operation=PS_EE_RunTimeBlock2_Core4.EraseBlock
        EGDI_EE_RunTimeBlock2_Core4: start-on-event=GetDataIndex, operation=PS_EE_RunTimeBlock2_Core4.GetDataIndex
        EGES_EE_RunTimeBlock2_Core4: start-on-event=GetErrorStatus, operation=PS_EE_RunTimeBlock2_Core4.GetErrorStatus
        EINB_EE_RunTimeBlock2_Core4: start-on-event=InvalidateNvBlock, operation=PS_EE_RunTimeBlock2_Core4.InvalidateNvBlock
        ERBL_EE_RunTimeBlock2_Core4: start-on-event=ReadBlock, operation=PS_EE_RunTimeBlock2_Core4.ReadBlock
        ERPBL_EE_RunTimeBlock2_Core4: start-on-event=ReadPRAMBlock, operation=PS_EE_RunTimeBlock2_Core4.ReadPRAMBlock
        ERBD_EE_RunTimeBlock2_Core4: start-on-event=RestoreBlockDefaults, operation=PS_EE_RunTimeBlock2_Core4.RestoreBlockDefaults
        ERPBD_EE_RunTimeBlock2_Core4: start-on-event=RestorePRAMBlockDefaults, operation=PS_EE_RunTimeBlock2_Core4.RestorePRAMBlockDefaults
        ESBP_EE_RunTimeBlock2_Core4: start-on-event=SetBlockProtection, operation=PAdmin_EE_RunTimeBlock2_Core4.SetBlockProtection
        ESDI_EE_RunTimeBlock2_Core4: start-on-event=SetDataIndex, operation=PS_EE_RunTimeBlock2_Core4.SetDataIndex
        ESRS_EE_RunTimeBlock2_Core4: start-on-event=SetRamBlockStatus, operation=PS_EE_RunTimeBlock2_Core4.SetRamBlockStatus
        EWBL_EE_RunTimeBlock2_Core4: start-on-event=WriteBlock, operation=PS_EE_RunTimeBlock2_Core4.WriteBlock
        EWPBL_EE_RunTimeBlock2_Core4: start-on-event=WritePRAMBlock, operation=PS_EE_RunTimeBlock2_Core4.WritePRAMBlock
        EENB_EE_IMMOBILIZERMMKEY_StrIMM_4: start-on-event=EraseNvBlock, operation=PS_EE_IMMOBILIZERMMKEY_StrIMM_4.EraseBlock
        EGDI_EE_IMMOBILIZERMMKEY_StrIMM_4: start-on-event=GetDataIndex, operation=PS_EE_IMMOBILIZERMMKEY_StrIMM_4.GetDataIndex
        EGES_EE_IMMOBILIZERMMKEY_StrIMM_4: start-on-event=GetErrorStatus, operation=PS_EE_IMMOBILIZERMMKEY_StrIMM_4.GetErrorStatus
        EINB_EE_IMMOBILIZERMMKEY_StrIMM_4: start-on-event=InvalidateNvBlock, operation=PS_EE_IMMOBILIZERMMKEY_StrIMM_4.InvalidateNvBlock
        ERBL_EE_IMMOBILIZERMMKEY_StrIMM_4: start-on-event=ReadBlock, operation=PS_EE_IMMOBILIZERMMKEY_StrIMM_4.ReadBlock
        ERPBL_EE_IMMOBILIZERMMKEY_StrIMM_4: start-on-event=ReadPRAMBlock, operation=PS_EE_IMMOBILIZERMMKEY_StrIMM_4.ReadPRAMBlock
        ERBD_EE_IMMOBILIZERMMKEY_StrIMM_4: start-on-event=RestoreBlockDefaults, operation=PS_EE_IMMOBILIZERMMKEY_StrIMM_4.RestoreBlockDefaults
        ERPBD_EE_IMMOBILIZERMMKEY_StrIMM_4: start-on-event=RestorePRAMBlockDefaults, operation=PS_EE_IMMOBILIZERMMKEY_StrIMM_4.RestorePRAMBlockDefaults
        ESBP_EE_IMMOBILIZERMMKEY_StrIMM_4: start-on-event=SetBlockProtection, operation=PAdmin_EE_IMMOBILIZERMMKEY_StrIMM_4.SetBlockProtection
        ESDI_EE_IMMOBILIZERMMKEY_StrIMM_4: start-on-event=SetDataIndex, operation=PS_EE_IMMOBILIZERMMKEY_StrIMM_4.SetDataIndex
        ESRS_EE_IMMOBILIZERMMKEY_StrIMM_4: start-on-event=SetRamBlockStatus, operation=PS_EE_IMMOBILIZERMMKEY_StrIMM_4.SetRamBlockStatus
        EWBL_EE_IMMOBILIZERMMKEY_StrIMM_4: start-on-event=WriteBlock, operation=PS_EE_IMMOBILIZERMMKEY_StrIMM_4.WriteBlock
        EWPBL_EE_IMMOBILIZERMMKEY_StrIMM_4: start-on-event=WritePRAMBlock, operation=PS_EE_IMMOBILIZERMMKEY_StrIMM_4.WritePRAMBlock
        EENB_Expendable_NonVolatile_4: start-on-event=EraseNvBlock, operation=PS_Expendable_NonVolatile_4.EraseBlock
        EGDI_Expendable_NonVolatile_4: start-on-event=GetDataIndex, operation=PS_Expendable_NonVolatile_4.GetDataIndex
        EGES_Expendable_NonVolatile_4: start-on-event=GetErrorStatus, operation=PS_Expendable_NonVolatile_4.GetErrorStatus
        EINB_Expendable_NonVolatile_4: start-on-event=InvalidateNvBlock, operation=PS_Expendable_NonVolatile_4.InvalidateNvBlock
        ERBL_Expendable_NonVolatile_4: start-on-event=ReadBlock, operation=PS_Expendable_NonVolatile_4.ReadBlock
        ERPBL_Expendable_NonVolatile_4: start-on-event=ReadPRAMBlock, operation=PS_Expendable_NonVolatile_4.ReadPRAMBlock
        ERBD_Expendable_NonVolatile_4: start-on-event=RestoreBlockDefaults, operation=PS_Expendable_NonVolatile_4.RestoreBlockDefaults
        ERPBD_Expendable_NonVolatile_4: start-on-event=RestorePRAMBlockDefaults, operation=PS_Expendable_NonVolatile_4.RestorePRAMBlockDefaults
        ESBP_Expendable_NonVolatile_4: start-on-event=SetBlockProtection, operation=PAdmin_Expendable_NonVolatile_4.SetBlockProtection
        ESDI_Expendable_NonVolatile_4: start-on-event=SetDataIndex, operation=PS_Expendable_NonVolatile_4.SetDataIndex
        ESRS_Expendable_NonVolatile_4: start-on-event=SetRamBlockStatus, operation=PS_Expendable_NonVolatile_4.SetRamBlockStatus
        EWBL_Expendable_NonVolatile_4: start-on-event=WriteBlock, operation=PS_Expendable_NonVolatile_4.WriteBlock
        EWPBL_Expendable_NonVolatile_4: start-on-event=WritePRAMBlock, operation=PS_Expendable_NonVolatile_4.WritePRAMBlock
        EENB_Cumulative_NonVolatile_4: start-on-event=EraseNvBlock, operation=PS_Cumulative_NonVolatile_4.EraseBlock
        EGDI_Cumulative_NonVolatile_4: start-on-event=GetDataIndex, operation=PS_Cumulative_NonVolatile_4.GetDataIndex
        EGES_Cumulative_NonVolatile_4: start-on-event=GetErrorStatus, operation=PS_Cumulative_NonVolatile_4.GetErrorStatus
        EINB_Cumulative_NonVolatile_4: start-on-event=InvalidateNvBlock, operation=PS_Cumulative_NonVolatile_4.InvalidateNvBlock
        ERBL_Cumulative_NonVolatile_4: start-on-event=ReadBlock, operation=PS_Cumulative_NonVolatile_4.ReadBlock
        ERPBL_Cumulative_NonVolatile_4: start-on-event=ReadPRAMBlock, operation=PS_Cumulative_NonVolatile_4.ReadPRAMBlock
        ERBD_Cumulative_NonVolatile_4: start-on-event=RestoreBlockDefaults, operation=PS_Cumulative_NonVolatile_4.RestoreBlockDefaults
        ERPBD_Cumulative_NonVolatile_4: start-on-event=RestorePRAMBlockDefaults, operation=PS_Cumulative_NonVolatile_4.RestorePRAMBlockDefaults
        ESBP_Cumulative_NonVolatile_4: start-on-event=SetBlockProtection, operation=PAdmin_Cumulative_NonVolatile_4.SetBlockProtection
        ESDI_Cumulative_NonVolatile_4: start-on-event=SetDataIndex, operation=PS_Cumulative_NonVolatile_4.SetDataIndex
        ESRS_Cumulative_NonVolatile_4: start-on-event=SetRamBlockStatus, operation=PS_Cumulative_NonVolatile_4.SetRamBlockStatus
        EWBL_Cumulative_NonVolatile_4: start-on-event=WriteBlock, operation=PS_Cumulative_NonVolatile_4.WriteBlock
        EWPBL_Cumulative_NonVolatile_4: start-on-event=WritePRAMBlock, operation=PS_Cumulative_NonVolatile_4.WritePRAMBlock
        EENB_Adaptive_NonVolatile_4: start-on-event=EraseNvBlock, operation=PS_Adaptive_NonVolatile_4.EraseBlock
        EGDI_Adaptive_NonVolatile_4: start-on-event=GetDataIndex, operation=PS_Adaptive_NonVolatile_4.GetDataIndex
        EGES_Adaptive_NonVolatile_4: start-on-event=GetErrorStatus, operation=PS_Adaptive_NonVolatile_4.GetErrorStatus
        EINB_Adaptive_NonVolatile_4: start-on-event=InvalidateNvBlock, operation=PS_Adaptive_NonVolatile_4.InvalidateNvBlock
        ERBL_Adaptive_NonVolatile_4: start-on-event=ReadBlock, operation=PS_Adaptive_NonVolatile_4.ReadBlock
        ERPBL_Adaptive_NonVolatile_4: start-on-event=ReadPRAMBlock, operation=PS_Adaptive_NonVolatile_4.ReadPRAMBlock
        ERBD_Adaptive_NonVolatile_4: start-on-event=RestoreBlockDefaults, operation=PS_Adaptive_NonVolatile_4.RestoreBlockDefaults
        ERPBD_Adaptive_NonVolatile_4: start-on-event=RestorePRAMBlockDefaults, operation=PS_Adaptive_NonVolatile_4.RestorePRAMBlockDefaults
        ESBP_Adaptive_NonVolatile_4: start-on-event=SetBlockProtection, operation=PAdmin_Adaptive_NonVolatile_4.SetBlockProtection
        ESDI_Adaptive_NonVolatile_4: start-on-event=SetDataIndex, operation=PS_Adaptive_NonVolatile_4.SetDataIndex
        ESRS_Adaptive_NonVolatile_4: start-on-event=SetRamBlockStatus, operation=PS_Adaptive_NonVolatile_4.SetRamBlockStatus
        EWBL_Adaptive_NonVolatile_4: start-on-event=WriteBlock, operation=PS_Adaptive_NonVolatile_4.WriteBlock
        EWPBL_Adaptive_NonVolatile_4: start-on-event=WritePRAMBlock, operation=PS_Adaptive_NonVolatile_4.WritePRAMBlock
        EENB_Static_NonVolatile_4: start-on-event=EraseNvBlock, operation=PS_Static_NonVolatile_4.EraseBlock
        EGDI_Static_NonVolatile_4: start-on-event=GetDataIndex, operation=PS_Static_NonVolatile_4.GetDataIndex
        EGES_Static_NonVolatile_4: start-on-event=GetErrorStatus, operation=PS_Static_NonVolatile_4.GetErrorStatus
        EINB_Static_NonVolatile_4: start-on-event=InvalidateNvBlock, operation=PS_Static_NonVolatile_4.InvalidateNvBlock
        ERBL_Static_NonVolatile_4: start-on-event=ReadBlock, operation=PS_Static_NonVolatile_4.ReadBlock
        ERPBL_Static_NonVolatile_4: start-on-event=ReadPRAMBlock, operation=PS_Static_NonVolatile_4.ReadPRAMBlock
        ERBD_Static_NonVolatile_4: start-on-event=RestoreBlockDefaults, operation=PS_Static_NonVolatile_4.RestoreBlockDefaults
        ERPBD_Static_NonVolatile_4: start-on-event=RestorePRAMBlockDefaults, operation=PS_Static_NonVolatile_4.RestorePRAMBlockDefaults
        ESBP_Static_NonVolatile_4: start-on-event=SetBlockProtection, operation=PAdmin_Static_NonVolatile_4.SetBlockProtection
        ESDI_Static_NonVolatile_4: start-on-event=SetDataIndex, operation=PS_Static_NonVolatile_4.SetDataIndex
        ESRS_Static_NonVolatile_4: start-on-event=SetRamBlockStatus, operation=PS_Static_NonVolatile_4.SetRamBlockStatus
        EWBL_Static_NonVolatile_4: start-on-event=WriteBlock, operation=PS_Static_NonVolatile_4.WriteBlock
        EWPBL_Static_NonVolatile_4: start-on-event=WritePRAMBlock, operation=PS_Static_NonVolatile_4.WritePRAMBlock
        EENB_EE_RunTimeBlock1_Core4: start-on-event=EraseNvBlock, operation=PS_EE_RunTimeBlock1_Core4.EraseBlock
        EGDI_EE_RunTimeBlock1_Core4: start-on-event=GetDataIndex, operation=PS_EE_RunTimeBlock1_Core4.GetDataIndex
        EGES_EE_RunTimeBlock1_Core4: start-on-event=GetErrorStatus, operation=PS_EE_RunTimeBlock1_Core4.GetErrorStatus
        EINB_EE_RunTimeBlock1_Core4: start-on-event=InvalidateNvBlock, operation=PS_EE_RunTimeBlock1_Core4.InvalidateNvBlock
        ERBL_EE_RunTimeBlock1_Core4: start-on-event=ReadBlock, operation=PS_EE_RunTimeBlock1_Core4.ReadBlock
        ERPBL_EE_RunTimeBlock1_Core4: start-on-event=ReadPRAMBlock, operation=PS_EE_RunTimeBlock1_Core4.ReadPRAMBlock
        ERBD_EE_RunTimeBlock1_Core4: start-on-event=RestoreBlockDefaults, operation=PS_EE_RunTimeBlock1_Core4.RestoreBlockDefaults
        ERPBD_EE_RunTimeBlock1_Core4: start-on-event=RestorePRAMBlockDefaults, operation=PS_EE_RunTimeBlock1_Core4.RestorePRAMBlockDefaults
        ESBP_EE_RunTimeBlock1_Core4: start-on-event=SetBlockProtection, operation=PAdmin_EE_RunTimeBlock1_Core4.SetBlockProtection
        ESDI_EE_RunTimeBlock1_Core4: start-on-event=SetDataIndex, operation=PS_EE_RunTimeBlock1_Core4.SetDataIndex
        ESRS_EE_RunTimeBlock1_Core4: start-on-event=SetRamBlockStatus, operation=PS_EE_RunTimeBlock1_Core4.SetRamBlockStatus
        EWBL_EE_RunTimeBlock1_Core4: start-on-event=WriteBlock, operation=PS_EE_RunTimeBlock1_Core4.WriteBlock
        EWPBL_EE_RunTimeBlock1_Core4: start-on-event=WritePRAMBlock, operation=PS_EE_RunTimeBlock1_Core4.WritePRAMBlock
        EENB_FE_4: start-on-event=EraseNvBlock, operation=PS_FE_4.EraseBlock
        EGDI_FE_4: start-on-event=GetDataIndex, operation=PS_FE_4.GetDataIndex
        EGES_FE_4: start-on-event=GetErrorStatus, operation=PS_FE_4.GetErrorStatus
        EINB_FE_4: start-on-event=InvalidateNvBlock, operation=PS_FE_4.InvalidateNvBlock
        ERBL_FE_4: start-on-event=ReadBlock, operation=PS_FE_4.ReadBlock
        ERPBL_FE_4: start-on-event=ReadPRAMBlock, operation=PS_FE_4.ReadPRAMBlock
        ERBD_FE_4: start-on-event=RestoreBlockDefaults, operation=PS_FE_4.RestoreBlockDefaults
        ERPBD_FE_4: start-on-event=RestorePRAMBlockDefaults, operation=PS_FE_4.RestorePRAMBlockDefaults
        ESBP_FE_4: start-on-event=SetBlockProtection, operation=PAdmin_FE_4.SetBlockProtection
        ESDI_FE_4: start-on-event=SetDataIndex, operation=PS_FE_4.SetDataIndex
        ESRS_FE_4: start-on-event=SetRamBlockStatus, operation=PS_FE_4.SetRamBlockStatus
        EWBL_FE_4: start-on-event=WriteBlock, operation=PS_FE_4.WriteBlock
        EWPBL_FE_4: start-on-event=WritePRAMBlock, operation=PS_FE_4.WritePRAMBlock
        EENB_Cumulative_NonVolatile_0: start-on-event=EraseNvBlock, operation=PS_Cumulative_NonVolatile_0.EraseBlock
        EGDI_Cumulative_NonVolatile_0: start-on-event=GetDataIndex, operation=PS_Cumulative_NonVolatile_0.GetDataIndex
        EGES_Cumulative_NonVolatile_0: start-on-event=GetErrorStatus, operation=PS_Cumulative_NonVolatile_0.GetErrorStatus
        EINB_Cumulative_NonVolatile_0: start-on-event=InvalidateNvBlock, operation=PS_Cumulative_NonVolatile_0.InvalidateNvBlock
        ERBL_Cumulative_NonVolatile_0: start-on-event=ReadBlock, operation=PS_Cumulative_NonVolatile_0.ReadBlock
        ERPBL_Cumulative_NonVolatile_0: start-on-event=ReadPRAMBlock, operation=PS_Cumulative_NonVolatile_0.ReadPRAMBlock
        ERBD_Cumulative_NonVolatile_0: start-on-event=RestoreBlockDefaults, operation=PS_Cumulative_NonVolatile_0.RestoreBlockDefaults
        ERPBD_Cumulative_NonVolatile_0: start-on-event=RestorePRAMBlockDefaults, operation=PS_Cumulative_NonVolatile_0.RestorePRAMBlockDefaults
        ESBP_Cumulative_NonVolatile_0: start-on-event=SetBlockProtection, operation=PAdmin_Cumulative_NonVolatile_0.SetBlockProtection
        ESDI_Cumulative_NonVolatile_0: start-on-event=SetDataIndex, operation=PS_Cumulative_NonVolatile_0.SetDataIndex
        ESRS_Cumulative_NonVolatile_0: start-on-event=SetRamBlockStatus, operation=PS_Cumulative_NonVolatile_0.SetRamBlockStatus
        EWBL_Cumulative_NonVolatile_0: start-on-event=WriteBlock, operation=PS_Cumulative_NonVolatile_0.WriteBlock
        EWPBL_Cumulative_NonVolatile_0: start-on-event=WritePRAMBlock, operation=PS_Cumulative_NonVolatile_0.WritePRAMBlock
        EENB_BSWDiag_Data_blk_Desc_Core0: start-on-event=EraseNvBlock, operation=PS_BSWDiag_Data_blk_Desc_Core0.EraseBlock
        EGDI_BSWDiag_Data_blk_Desc_Core0: start-on-event=GetDataIndex, operation=PS_BSWDiag_Data_blk_Desc_Core0.GetDataIndex
        EGES_BSWDiag_Data_blk_Desc_Core0: start-on-event=GetErrorStatus, operation=PS_BSWDiag_Data_blk_Desc_Core0.GetErrorStatus
        EINB_BSWDiag_Data_blk_Desc_Core0: start-on-event=InvalidateNvBlock, operation=PS_BSWDiag_Data_blk_Desc_Core0.InvalidateNvBlock
        ERBL_BSWDiag_Data_blk_Desc_Core0: start-on-event=ReadBlock, operation=PS_BSWDiag_Data_blk_Desc_Core0.ReadBlock
        ERPBL_BSWDiag_Data_blk_Desc_Core0: start-on-event=ReadPRAMBlock, operation=PS_BSWDiag_Data_blk_Desc_Core0.ReadPRAMBlock
        ERBD_BSWDiag_Data_blk_Desc_Core0: start-on-event=RestoreBlockDefaults, operation=PS_BSWDiag_Data_blk_Desc_Core0.RestoreBlockDefaults
        ERPBD_BSWDiag_Data_blk_Desc_Core0: start-on-event=RestorePRAMBlockDefaults, operation=PS_BSWDiag_Data_blk_Desc_Core0.RestorePRAMBlockDefaults
        ESBP_BSWDiag_Data_blk_Desc_Core0: start-on-event=SetBlockProtection, operation=PAdmin_BSWDiag_Data_blk_Desc_Core0.SetBlockProtection
        ESDI_BSWDiag_Data_blk_Desc_Core0: start-on-event=SetDataIndex, operation=PS_BSWDiag_Data_blk_Desc_Core0.SetDataIndex
        ESRS_BSWDiag_Data_blk_Desc_Core0: start-on-event=SetRamBlockStatus, operation=PS_BSWDiag_Data_blk_Desc_Core0.SetRamBlockStatus
        EWBL_BSWDiag_Data_blk_Desc_Core0: start-on-event=WriteBlock, operation=PS_BSWDiag_Data_blk_Desc_Core0.WriteBlock
        EWPBL_BSWDiag_Data_blk_Desc_Core0: start-on-event=WritePRAMBlock, operation=PS_BSWDiag_Data_blk_Desc_Core0.WritePRAMBlock
      port-api-options:
        {enable-take-address=false, indirect-api=false, port-defined-argument-value{value=NvMConf_NvMBlockDescriptor_NvM_MultiBlock, value-type=NvM_BlockIdType}, port=PS_NvM_MultiBlock}
        {enable-take-address=false, indirect-api=false, port-defined-argument-value{value=NvMConf_NvMBlockDescriptor_NvM_MultiBlock, value-type=NvM_BlockIdType}, port=PAdmin_NvM_MultiBlock}
        {enable-take-address=false, indirect-api=false, port-defined-argument-value{value=NvMConf_NvMBlockDescriptor_Expendable_NonVolatile_0, value-type=NvM_BlockIdType}, port=PS_Expendable_NonVolatile_0}
        {enable-take-address=false, indirect-api=false, port-defined-argument-value{value=NvMConf_NvMBlockDescriptor_Expendable_NonVolatile_0, value-type=NvM_BlockIdType}, port=PAdmin_Expendable_NonVolatile_0}
        {enable-take-address=false, indirect-api=false, port-defined-argument-value{value=NvMConf_NvMBlockDescriptor_Static_NonVolatile_0, value-type=NvM_BlockIdType}, port=PS_Static_NonVolatile_0}
        {enable-take-address=false, indirect-api=false, port-defined-argument-value{value=NvMConf_NvMBlockDescriptor_Static_NonVolatile_0, value-type=NvM_BlockIdType}, port=PAdmin_Static_NonVolatile_0}
        {enable-take-address=false, indirect-api=false, port-defined-argument-value{value=NvMConf_NvMBlockDescriptor_EE_PEDAL_SENSOR_StrIMM_0, value-type=NvM_BlockIdType}, port=PS_EE_PEDAL_SENSOR_StrIMM_0}
        {enable-take-address=false, indirect-api=false, port-defined-argument-value{value=NvMConf_NvMBlockDescriptor_EE_PEDAL_SENSOR_StrIMM_0, value-type=NvM_BlockIdType}, port=PAdmin_EE_PEDAL_SENSOR_StrIMM_0}
        {enable-take-address=false, indirect-api=false, port-defined-argument-value{value=NvMConf_NvMBlockDescriptor_EE_RunTimeBlock1_Core0, value-type=NvM_BlockIdType}, port=PS_EE_RunTimeBlock1_Core0}
        {enable-take-address=false, indirect-api=false, port-defined-argument-value{value=NvMConf_NvMBlockDescriptor_EE_RunTimeBlock1_Core0, value-type=NvM_BlockIdType}, port=PAdmin_EE_RunTimeBlock1_Core0}
        {enable-take-address=false, indirect-api=false, port-defined-argument-value{value=NvMConf_NvMBlockDescriptor_Expendable_NonVolatile_1, value-type=NvM_BlockIdType}, port=PS_Expendable_NonVolatile_1}
        {enable-take-address=false, indirect-api=false, port-defined-argument-value{value=NvMConf_NvMBlockDescriptor_Expendable_NonVolatile_1, value-type=NvM_BlockIdType}, port=PAdmin_Expendable_NonVolatile_1}
        {enable-take-address=false, indirect-api=false, port-defined-argument-value{value=NvMConf_NvMBlockDescriptor_Expendable_NonVolatile_Core2, value-type=NvM_BlockIdType}, port=PS_Expendable_NonVolatile_Core2}
        {enable-take-address=false, indirect-api=false, port-defined-argument-value{value=NvMConf_NvMBlockDescriptor_Expendable_NonVolatile_Core2, value-type=NvM_BlockIdType}, port=PAdmin_Expendable_NonVolatile_Core2}
        {enable-take-address=false, indirect-api=false, port-defined-argument-value{value=NvMConf_NvMBlockDescriptor_Expendable_NonVolatile_3, value-type=NvM_BlockIdType}, port=PS_Expendable_NonVolatile_3}
        {enable-take-address=false, indirect-api=false, port-defined-argument-value{value=NvMConf_NvMBlockDescriptor_Expendable_NonVolatile_3, value-type=NvM_BlockIdType}, port=PAdmin_Expendable_NonVolatile_3}
        {enable-take-address=false, indirect-api=false, port-defined-argument-value{value=NvMConf_NvMBlockDescriptor_Cumulative_NonVolatile_1, value-type=NvM_BlockIdType}, port=PS_Cumulative_NonVolatile_1}
        {enable-take-address=false, indirect-api=false, port-defined-argument-value{value=NvMConf_NvMBlockDescriptor_Cumulative_NonVolatile_1, value-type=NvM_BlockIdType}, port=PAdmin_Cumulative_NonVolatile_1}
        {enable-take-address=false, indirect-api=false, port-defined-argument-value{value=NvMConf_NvMBlockDescriptor_EE_IMMOBYPASSCNTR_StrIMM_4, value-type=NvM_BlockIdType}, port=PS_EE_IMMOBYPASSCNTR_StrIMM_4}
        {enable-take-address=false, indirect-api=false, port-defined-argument-value{value=NvMConf_NvMBlockDescriptor_EE_IMMOBYPASSCNTR_StrIMM_4, value-type=NvM_BlockIdType}, port=PAdmin_EE_IMMOBYPASSCNTR_StrIMM_4}
        {enable-take-address=false, indirect-api=false, port-defined-argument-value{value=NvMConf_NvMBlockDescriptor_EE_IMMOBILIZERAUTHSTAT_StrIMM_4, value-type=NvM_BlockIdType}, port=PS_EE_IMMOBILIZERAUTHSTAT_StrIMM_4}
        {enable-take-address=false, indirect-api=false, port-defined-argument-value{value=NvMConf_NvMBlockDescriptor_EE_IMMOBILIZERAUTHSTAT_StrIMM_4, value-type=NvM_BlockIdType}, port=PAdmin_EE_IMMOBILIZERAUTHSTAT_StrIMM_4}
        {enable-take-address=false, indirect-api=false, port-defined-argument-value{value=NvMConf_NvMBlockDescriptor_EE_RunTimeBlock2_Core4, value-type=NvM_BlockIdType}, port=PS_EE_RunTimeBlock2_Core4}
        {enable-take-address=false, indirect-api=false, port-defined-argument-value{value=NvMConf_NvMBlockDescriptor_EE_RunTimeBlock2_Core4, value-type=NvM_BlockIdType}, port=PAdmin_EE_RunTimeBlock2_Core4}
        {enable-take-address=false, indirect-api=false, port-defined-argument-value{value=NvMConf_NvMBlockDescriptor_EE_IMMOBILIZERMMKEY_StrIMM_4, value-type=NvM_BlockIdType}, port=PS_EE_IMMOBILIZERMMKEY_StrIMM_4}
        {enable-take-address=false, indirect-api=false, port-defined-argument-value{value=NvMConf_NvMBlockDescriptor_EE_IMMOBILIZERMMKEY_StrIMM_4, value-type=NvM_BlockIdType}, port=PAdmin_EE_IMMOBILIZERMMKEY_StrIMM_4}
        {enable-take-address=false, indirect-api=false, port-defined-argument-value{value=NvMConf_NvMBlockDescriptor_Expendable_NonVolatile_4, value-type=NvM_BlockIdType}, port=PS_Expendable_NonVolatile_4}
        {enable-take-address=false, indirect-api=false, port-defined-argument-value{value=NvMConf_NvMBlockDescriptor_Expendable_NonVolatile_4, value-type=NvM_BlockIdType}, port=PAdmin_Expendable_NonVolatile_4}
        {enable-take-address=false, indirect-api=false, port-defined-argument-value{value=NvMConf_NvMBlockDescriptor_Cumulative_NonVolatile_4, value-type=NvM_BlockIdType}, port=PS_Cumulative_NonVolatile_4}
        {enable-take-address=false, indirect-api=false, port-defined-argument-value{value=NvMConf_NvMBlockDescriptor_Cumulative_NonVolatile_4, value-type=NvM_BlockIdType}, port=PAdmin_Cumulative_NonVolatile_4}
        {enable-take-address=false, indirect-api=false, port-defined-argument-value{value=NvMConf_NvMBlockDescriptor_Adaptive_NonVolatile_4, value-type=NvM_BlockIdType}, port=PS_Adaptive_NonVolatile_4}
        {enable-take-address=false, indirect-api=false, port-defined-argument-value{value=NvMConf_NvMBlockDescriptor_Adaptive_NonVolatile_4, value-type=NvM_BlockIdType}, port=PAdmin_Adaptive_NonVolatile_4}
        {enable-take-address=false, indirect-api=false, port-defined-argument-value{value=NvMConf_NvMBlockDescriptor_Static_NonVolatile_4, value-type=NvM_BlockIdType}, port=PS_Static_NonVolatile_4}
        {enable-take-address=false, indirect-api=false, port-defined-argument-value{value=NvMConf_NvMBlockDescriptor_Static_NonVolatile_4, value-type=NvM_BlockIdType}, port=PAdmin_Static_NonVolatile_4}
        {enable-take-address=false, indirect-api=false, port-defined-argument-value{value=NvMConf_NvMBlockDescriptor_EE_RunTimeBlock1_Core4, value-type=NvM_BlockIdType}, port=PS_EE_RunTimeBlock1_Core4}
        {enable-take-address=false, indirect-api=false, port-defined-argument-value{value=NvMConf_NvMBlockDescriptor_EE_RunTimeBlock1_Core4, value-type=NvM_BlockIdType}, port=PAdmin_EE_RunTimeBlock1_Core4}
        {enable-take-address=false, indirect-api=false, port-defined-argument-value{value=NvMConf_NvMBlockDescriptor_FE_4, value-type=NvM_BlockIdType}, port=PS_FE_4}
        {enable-take-address=false, indirect-api=false, port-defined-argument-value{value=NvMConf_NvMBlockDescriptor_FE_4, value-type=NvM_BlockIdType}, port=PAdmin_FE_4}
        {enable-take-address=false, indirect-api=false, port-defined-argument-value{value=NvMConf_NvMBlockDescriptor_Cumulative_NonVolatile_0, value-type=NvM_BlockIdType}, port=PS_Cumulative_NonVolatile_0}
        {enable-take-address=false, indirect-api=false, port-defined-argument-value{value=NvMConf_NvMBlockDescriptor_Cumulative_NonVolatile_0, value-type=NvM_BlockIdType}, port=PAdmin_Cumulative_NonVolatile_0}
        {enable-take-address=false, indirect-api=false, port-defined-argument-value{value=NvMConf_NvMBlockDescriptor_BSWDiag_Data_blk_Desc_Core0, value-type=NvM_BlockIdType}, port=PS_BSWDiag_Data_blk_Desc_Core0}
        {enable-take-address=false, indirect-api=false, port-defined-argument-value{value=NvMConf_NvMBlockDescriptor_BSWDiag_Data_blk_Desc_Core0, value-type=NvM_BlockIdType}, port=PAdmin_BSWDiag_Data_blk_Desc_Core0}
      14 x runnable:
        EraseNvBlock: runnable-entity-argument=symbol=BlockId, can-be-invoked-concurrently=true, symbol=NvM_EraseNvBlock
        GetDataIndex: arguments=[symbol=BlockId, symbol=DataIndexPtr], can-be-invoked-concurrently=true, symbol=NvM_GetDataIndex
        GetErrorStatus: arguments=[symbol=BlockId, symbol=RequestResultPtr], can-be-invoked-concurrently=true, symbol=NvM_GetErrorStatus
        InvalidateNvBlock: runnable-entity-argument=symbol=BlockId, can-be-invoked-concurrently=true, symbol=NvM_InvalidateNvBlock
        ReadBlock: arguments=[symbol=BlockId, symbol=NvM_DstPtr], can-be-invoked-concurrently=true, symbol=NvM_ReadBlock
        ReadPRAMBlock: runnable-entity-argument=symbol=BlockId, can-be-invoked-concurrently=true, symbol=NvM_ReadPRAMBlock
        RestoreBlockDefaults: arguments=[symbol=BlockId, symbol=NvM_DstPtr], can-be-invoked-concurrently=true, symbol=NvM_RestoreBlockDefaults
        RestorePRAMBlockDefaults: runnable-entity-argument=symbol=BlockId, can-be-invoked-concurrently=true, symbol=NvM_RestorePRAMBlockDefaults
        SetBlockProtection: arguments=[symbol=BlockId, symbol=ProtectionEnabled], can-be-invoked-concurrently=true, symbol=NvM_SetBlockProtection
        SetDataIndex: arguments=[symbol=BlockId, symbol=DataIndex], can-be-invoked-concurrently=true, symbol=NvM_SetDataIndex
        SetRamBlockStatus: arguments=[symbol=BlockId, symbol=BlockChanged], can-be-invoked-concurrently=true, symbol=NvM_SetRamBlockStatus
        WriteBlock: arguments=[symbol=BlockId, symbol=NvM_SrcPtr], can-be-invoked-concurrently=true, symbol=NvM_WriteBlock
        WritePRAMBlock: runnable-entity-argument=symbol=BlockId, can-be-invoked-concurrently=true, symbol=NvM_WritePRAMBlock
        MainFunction: symbol=NvM_MainFunction
